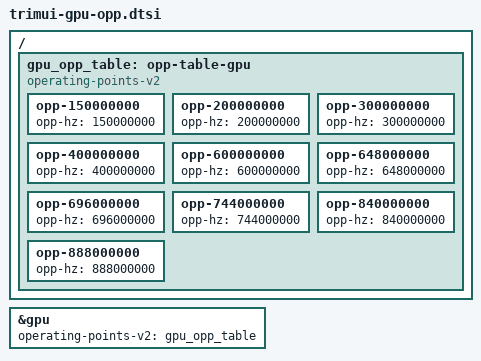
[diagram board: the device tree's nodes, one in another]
// SPDX-License-Identifier: (GPL-2.0-only OR MIT)
// Copyright (C) 2026 Midgy BALON
/*
 * STAGING — Mali-G57 GPU DVFS (devfreq) OPP table. Optional, off the critical path.
 *
 * GATED on an upstream clock fix (this was previously — wrongly — believed free-
 * standing). The A523/T527 GPU mod clock (0x670) is a CYCLE-MASKING / fractional
 * divider: rate = source * (16 - M) / 16, NOT a linear M+1 divider. Mainline still
 * models it as linear, so every OPP needing M>0 SILENTLY OVERCLOCKS the Mali: on
 * hardware "150 MHz" runs at ~487 MHz, "200"->648, "300"->560, "400"->750 (25% over
 * the vendor ceiling — thermal throttling to "400" actually RAISES the clock).
 * Measured by Juan Manuel Lopez Carrillo (ut-slayer) on an OrangePi 4A with the Mali
 * cycle counter; the fractional model was confirmed by Chen-Yu Tsai.
 *   -> DO NOT enable this table until the fix lands. His series "clk: sunxi-ng: fix
 *      the A523/T527 GPU clock model, enable GPU DVFS" is now at v2 (linux-sunxi,
 *      2026-08-03, base sunxi/for-next): (1) adds a ccu_maskdiv clock type, (2) switches
 *      the A523 gpu_clk to it + drops the pll-periph0-800M parent + drops
 *      CLK_SET_RATE_PARENT (the v1 pll-gpu notifier was DROPPED — pll-gpu is pinned once
 *      via assigned-clock-rates instead), (3) **puts the 150/200/300/400/600 MHz OPP
 *      table straight into sun55i-a523.dtsi** with opp-microvolt = <900000 900000 920000>
 *      and the operating-points-v2 ref in the SoC gpu node. So once it merges our board
 *      inherits the table AND the ref FOR FREE from the .dtsi -> **DELETE THIS FILE then**
 *      (shipping it would duplicate the gpu_opp_table label + operating-points-v2 = DT
 *      conflict). Track to merge; do NOT cherry-pick the in-review v2. A v3 is likely
 *      (Sashiko-bot/Chen-Yu review nits). Our fixed-920mV dcdc2 rail is exactly the
 *      "920 mV GPU rail" case his voltage ceiling was written for (transitions are no-ops).
 *   -> Only 200/300/400/600 MHz map to M=0 (exact under either model). 150 MHz and
 *      every turbo row below are wrong until the maskdiv fix (see the ceiling note).
 * HW-UNVERIFIED regardless. To use (POST-fix): #include from the board DTS after the
 * &gpu enable, or paste these nodes in.
 *
 * Frequencies = the VENDOR DTB `gpu-opp-table` (full 10-step ladder), confirmed
 * from the stock firmware. The vendor board DTB is BYTE-IDENTICAL between fw
 * v1.0.1 and v1.0.2 (md5 967f1c68…), so this table is current and authoritative.
 *   150 / 200 / 300 / 400 / 600 / 648 / 696 / 744 / 840 / 888 MHz.
 * (The earlier draft stopped at 600 MHz; the vendor ladder actually tops out at
 * 888 MHz. Vendor per-step microvolts run 900–1050 mV — see the comment below on
 * why they are NOT reproduced here.)
 *
 * Voltage is intentionally NOT scaled (clock-only OPP, no opp-microvolt):
 * mali-supply is AXP2202 dcdc2, a SHARED, regulator-always-on GPU+VE rail
 * (board DTS pins it at 920 mV). Per docs/GPU-NOTES.md it must be treated as a
 * static system rail, so Panfrost devfreq scales CLK_GPU ("core") only.
 *   -> IF the OPP core rejects this because mali-supply is bound, add an
 *      identical `opp-microvolt = <920000>;` to every row (a no-op on the fixed
 *      always-on rail — must match reg_dcdc2's constraint, NOT a lower value).
 *   -> Only add real per-step voltages if the GPU ever gets its own rail. The
 *      vendor voltages (for reference, if a dedicated rail appears) are:
 *      150–648 MHz @ 900 mV, 696 @ 920, 744/840 @ 1000, 888 @ 1050.
 *
 * HW-verify: that CLK_GPU actually reaches each rate — this is exactly the linear-
 * vs-masking bug above — and that the top rates are stable on the device. The 648+
 * MHz entries are the vendor "turbo"/speed-bin steps: they run from pll-gpu (a live
 * variable PLL, SID-efuse gated), which Juan's first series deliberately DEFERS to a
 * follow-up, so they are DOUBLY gated (maskdiv fix + the pll-gpu speed-bin work).
 * Keep the default ceiling conservative (600 MHz, the top M=0 universal rate) and
 * only raise it after both land + on-device thermal/stability testing on the fixed rail.
 *   -> HARD SAFETY CAP for THIS board: our mali-supply is a FIXED 920 mV rail. The
 *      vendor 744/840/888 steps need 1000/1000/1050 mV -> on a 920 mV rail they are
 *      UNDERVOLTED and will fault/hang. NEVER enable them here. The only turbo step
 *      reachable on 920 mV is 696 MHz (vendor @920 mV) and only if our SID speed bin
 *      sanctions it (READ THE SID ON-DEVICE). Practical ceiling for us = 600, or 696
 *      on a bin-1 part. That makes the upstream .dtsi 5-step table (150-600) the right
 *      fit as-is; 696 is a later single-row board add gated on the SID read.
 */

&gpu {
	operating-points-v2 = <&gpu_opp_table>;
};

/ {
	gpu_opp_table: opp-table-gpu {
		compatible = "operating-points-v2";

		opp-150000000 {
			opp-hz = /bits/ 64 <150000000>;
		};
		opp-200000000 {
			opp-hz = /bits/ 64 <200000000>;
		};
		opp-300000000 {
			opp-hz = /bits/ 64 <300000000>;
		};
		opp-400000000 {
			opp-hz = /bits/ 64 <400000000>;
		};
		opp-600000000 {
			opp-hz = /bits/ 64 <600000000>;
		};
		opp-648000000 {
			opp-hz = /bits/ 64 <648000000>;
		};
		opp-696000000 {
			opp-hz = /bits/ 64 <696000000>;
		};
		opp-744000000 {
			opp-hz = /bits/ 64 <744000000>;
		};
		opp-840000000 {
			opp-hz = /bits/ 64 <840000000>;
		};
		opp-888000000 {
			opp-hz = /bits/ 64 <888000000>;
		};
	};
};
